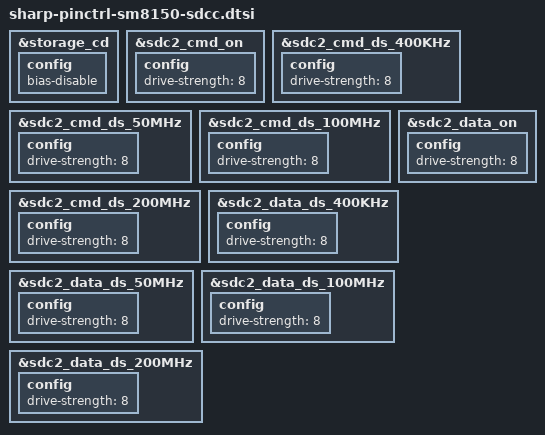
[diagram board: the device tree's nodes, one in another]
/* Copyright (c) 2016-2017, The Linux Foundation. All rights reserved.
 *
 * This program is free software; you can redistribute it and/or modify
 * it under the terms of the GNU General Public License version 2 and
 * only version 2 as published by the Free Software Foundation.
 *
 * This program is distributed in the hope that it will be useful,
 * but WITHOUT ANY WARRANTY; without even the implied warranty of
 * MERCHANTABILITY or FITNESS FOR A PARTICULAR PURPOSE.  See the
 * GNU General Public License for more details.
 */

&storage_cd {
	config {
		bias-disable;			/* non pull */
	};
};

&sdc2_cmd_on {
	config {
		drive-strength = <8>;	/* 8 MA */
	};
};

&sdc2_cmd_ds_400KHz {
	config {
		drive-strength = <8>;	/* 8 MA */
	};
};

&sdc2_cmd_ds_50MHz {
	config {
		drive-strength = <8>;	/* 8 MA */
	};
};

&sdc2_cmd_ds_100MHz {
	config {
		drive-strength = <8>;	/* 8 MA */
	};
};

&sdc2_cmd_ds_200MHz {
	config {
		drive-strength = <8>;	/* 8 MA */
	};
};

&sdc2_data_on {
	config {
		drive-strength = <8>;	/* 8 MA */
	};
};

&sdc2_data_ds_400KHz {
	config {
		drive-strength = <8>;	/* 8 MA */
	};
};

&sdc2_data_ds_50MHz {
	config {
		drive-strength = <8>;	/* 8 MA */
	};
};

&sdc2_data_ds_100MHz {
	config {
		drive-strength = <8>;	/* 8 MA */
	};
};

&sdc2_data_ds_200MHz {
	config {
		drive-strength = <8>;	/* 8 MA */
	};
};
